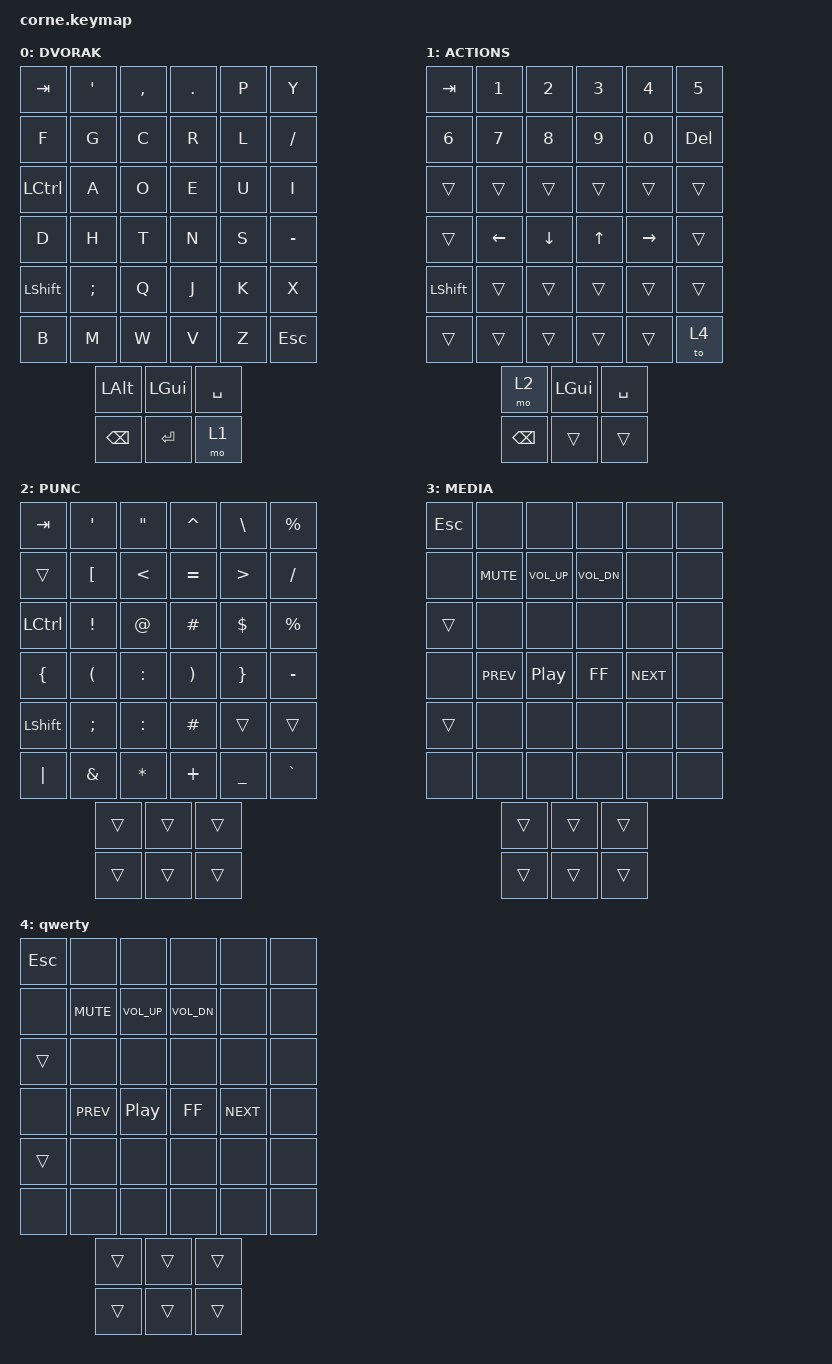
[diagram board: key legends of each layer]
/*
 * Copyright (c) 2020 The ZMK Contributors
 *
 * SPDX-License-Identifier: MIT
 */

#include <behaviors.dtsi>
#include <dt-bindings/zmk/keys.h>
#include <dt-bindings/zmk/bt.h>

/ {
        keymap {
                compatible = "zmk,keymap";

                dvorak_layer { //0
                        display-name = "DVORAK";
//DVORAK
// -----------------------------------------------------------------------------------------
// |  TAB |  '  |  <  |  >  |  P  |  Y  |   |  F  |  G   |  C  |  R  |  L  |  DEL  |
// | CTRL |  A  |  O  |  E  |  U  |  I  |   |  D  |  H   |  T  |  N  |  S  |  -   |
// | SHFT |  ;  |  Q  |  J  |  K  |  X  |   |  B  |  M   |  W  |  V  |  Z  | ESC  |
//                    | ALT | GUI | SPC |   | BSPC | ENTER  | ALT |
                        bindings = <
        &kp TAB   &kp SQT  &kp COMMA &kp DOT  &kp P &kp Y   
        &kp F &kp G &kp C &kp R &kp L &kp /

        &kp LCTRL &kp A &kp O &kp E &kp U &kp I   
        &kp D &kp H &kp T &kp N &kp S &kp MINUS

        &kp LSHFT &kp SEMI &kp Q &kp J &kp K &kp X   
        &kp B &kp M &kp W &kp V &kp Z &kp ESC

        &kp LALT &kp LEFT_GUI &kp SPACE   
        &kp BSPC &kp RET &mo 1
                        >;
                };
                quick_actions { //1
                         display-name = "ACTIONS";
//1 NUMBERS  + MOVE
// -----------------------------------------------------------------------------------------
// |  TAB |  1  |  2  |  3  |  4  |  5  |   |  6  |  7  |  8  |  9  |  0  | DEL |
// |      |     |     |     |     | to  |   |     | LFT | DWN |  UP |  RGT  |      |
// | SHFT |     |     |     |     |     |   |     |     |     |     |     |   TO NUMBPAD   |
//                    |  MO2   | GUI | SPC |   | BSPC | ENT | -- |
                        bindings = <
   &kp TAB    &kp N1       &kp N2       &kp N3       &kp N4       &kp N5         
   &kp N6   &kp N7   &kp N8 &kp N9    &kp N0 &kp DEL

   &trans   &trans 0 &trans &trans &trans &trans   
   &trans   &kp LEFT &kp DOWN &kp UP &kp RIGHT &trans

   &kp LSHFT  &trans       &trans       &trans       &trans       &trans         
   &trans   &trans   &trans &trans  &trans &to 4
                                    
   &mo 2 &kp LGUI &kp SPACE          
   &kp BSPC  &trans  &trans
                        >;
                };

                punctuation { //2
                        display-name = "PUNC";
//PUNCTUATION
// -----------------------------------------------------------------------------------------
// |  TAB |  '  |  "  |  ^  |  \  |  %  |   |  [  |  <  |  =  |  >  |  ]  | /   |
// | CTRL |  !  |  @  |  £  |  $  |  %  |   |  {  |  (  |  :  |  )  |  }  |  -  |
// | SHFT |  ;  |  :  |  #  |     |     |   | "|" |  &  |  *  |  +  |  _  |  `  |
//                    | --- | GUI | SPC |   | BSPC| ENT | --- |
                        bindings = <
   &kp  TAB  &kp APOS &kp DQT &kp CARET &kp BSLH &kp PRCNT   
   &trans &kp LEFT_BRACKET &kp LESS_THAN &kp EQUAL &kp GREATER_THAN &kp SLASH

   &kp LCTRL &kp EXCL &kp AT_SIGN &kp POUND  &kp DLLR  &kp PRCNT         
   &kp LEFT_BRACE &kp LPAR &kp COLON &kp RPAR &kp RIGHT_BRACE &kp MINUS

   &kp LSHFT &kp SEMI   &kp COLON &kp HASH   &trans   &trans      
   &kp PIPE &kp AMPERSAND  &kp ASTERISK  &kp PLUS &kp UNDER &kp GRAVE

   &trans   &trans   &trans  
   &trans   &trans   &trans
                        >;
                };
                media { //3
                display-name = "MEDIA";
//MEDIA
// -----------------------------------------------------------------------------------------
// |     |     |     |     |     |     | -  |     |             |   VOL DOWN    |    VOL UP     |       |     |
// |     |     |     |     |     |     | -  |     |  PREVIOUS   |   PLAY/PAUSE  |  PLAY/PAUSE   |  NEXT   |     |
// |     |     |     |     |     |     | -  |     |             |     |     |     |     |
//                   |     |     |     | -  |     |             |     |
                        bindings = <
   &kp ESC &none &none &none &none &none
   &none &kp C_MUTE &kp C_VOL_UP &kp C_VOL_DN &none &none

   &trans &none &none &none &none &none
   &none  &kp C_PREV &kp C_PLAY_PAUSE &kp C_FF &kp C_NEXT &none

   &trans &none &none &none &none &none
   &none  &none &none &none &none &none

   &trans &trans &trans
   &trans &trans &trans
                        >;
                };

                qwerty  { //4
//MEDIA
// -----------------------------------------------------------------------------------------
// |     |     |     |     |     |     | -  |     |             |   VOL DOWN    |    VOL UP     |       |     |
// |     |     |     |     |     |     | -  |     |  PREVIOUS   |   PLAY/PAUSE  |  PLAY/PAUSE   |  NEXT   |     |
// |     |     |     |     |     |     | -  |     |             |     |     |     |     |
//                   |     |     |     | -  |     |             |     |
                        bindings = <
   &kp ESC &none &none &none &none &none
   &none &kp C_MUTE &kp C_VOL_UP &kp C_VOL_DN &none &none

   &trans &none &none &none &none &none
   &none  &kp C_PREV &kp C_PLAY_PAUSE &kp C_FF &kp C_NEXT &none

   &trans &none &none &none &none &none
   &none  &none &none &none &none &none

   &trans &trans &trans
   &trans &trans &trans
                        >;
                };
        };
};
